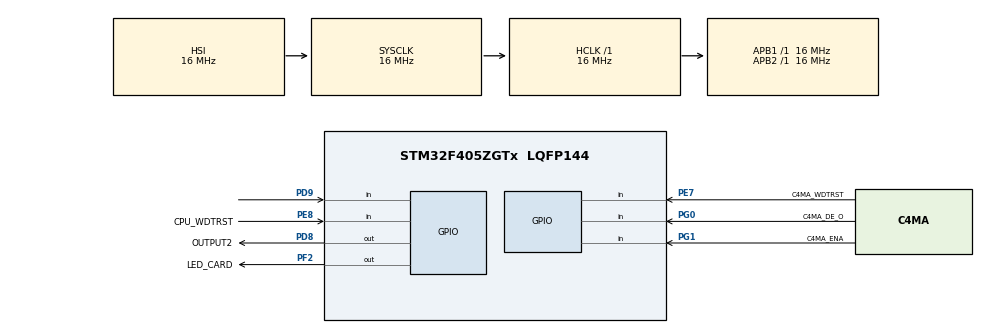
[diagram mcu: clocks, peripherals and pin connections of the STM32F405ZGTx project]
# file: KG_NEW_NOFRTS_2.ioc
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Mcu.Family=STM32F4
Mcu.Name=STM32F405ZGTx
Mcu.Package=LQFP144
NVIC.PriorityGroup=NVIC_PRIORITYGROUP_4
NVIC.TIM3_IRQn=true\:15\:0\:false\:false\:true\:false\:true\:true
NVIC.TimeBase=TIM3_IRQn
NVIC.TimeBaseIP=TIM3
PC12.Signal=UART5_TX
PD2.Signal=UART5_RX
PD8.GPIO_Label=OUTPUT2
PD8.Signal=GPIO_Output
PD9.Signal=GPIO_Input
PE7.GPIO_Label=C4MA_WDTRST
PE7.Signal=GPIO_Input
PE8.GPIO_Label=CPU_WDTRST
PE8.Signal=GPIO_Input
PF2.GPIO_Label=LED_CARD
PF2.Signal=GPIO_Output
PG0.GPIO_Label=C4MA_DE_O
PG0.Signal=GPIO_Input
PG1.GPIO_Label=C4MA_ENA
PG1.Signal=GPIO_Input
PH0-OSC_IN.Mode=HSE-External-Oscillator
PH0-OSC_IN.Signal=RCC_OSC_IN
PH1-OSC_OUT.Mode=HSE-External-Oscillator
PH1-OSC_OUT.Signal=RCC_OSC_OUT
ProjectManager.HeapSize=0x200
ProjectManager.StackSize=0x400
ProjectManager.TargetToolchain=STM32CubeIDE
RCC.48MHZClocksFreq_Value=75000000
RCC.AHBFreq_Value=16000000
RCC.APB1Freq_Value=16000000
RCC.APB2Freq_Value=16000000
RCC.CortexFreq_Value=16000000
RCC.HSE_VALUE=25000000
RCC.HSI_VALUE=16000000
RCC.LSE_VALUE=32768
RCC.PLLSourceVirtual=RCC_PLLSOURCE_HSE
RCC.SYSCLKFreq_VALUE=16000000
RCC.VCOOutputFreq_Value=300000000
VP_SYS_VS_tim3.Mode=TIM3
board=custom

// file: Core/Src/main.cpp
/* USER CODE BEGIN Header */
/**
  ******************************************************************************
  * @file           : main.c
  * @brief          : Main program body
  ******************************************************************************
  * @attention
  *
  * Copyright (c) 2022 STMicroelectronics.
  * All rights reserved.
  *
  * This software is licensed under terms that can be found in the LICENSE file
  * in the root directory of this software component.
  * If no LICENSE file comes with this software, it is provided AS-IS.
  *
  ******************************************************************************
  */
/* USER CODE END Header */
#include "../Inc/main.h"
//#include "usart.h"
#include "gpio.h"

/* USER CODE BEGIN Includes */
//#include "../Mods/RS485_E/M485_E.h"
#include "../Mods/GPIO/MGPIO.h"

/* USER CODE END Includes */

void SystemClock_Config(void);

/* USER CODE BEGIN 0 */
////----------------------------------------------------------------------------
//void HAL_UART_TxCpltCallback( UART_HandleTypeDef *huart ){
//  //__disable_irq();
//  if( huart == g485E.mhUart   )  g485E.onIT_TX();
//
//  //if( huart == gST7580.mhUart )  gST7580.onIT_TX();
// // __enable_irq();
// }//----------------------------------------------------------------------------
//
////----------------------------------------------------------------------------
//void HAL_UART_RxCpltCallback(UART_HandleTypeDef *huart ) {
// // __disable_irq();
//
//  if( huart == g485E.mhUart   )  g485E.onIT_RX();
//	//HAL_GPIO_TogglePin (LED_CARD_GPIO_Port, LED_CARD_Pin);
//	//HAL_UART_Receive_IT(  huart, mRXBuf, 1 );
//
//  //if( huart == gST7580.mhUart )  gST7580.onIT_RX();
//  //__enable_irq();
// }//----------------------------------------------------------------------------

/* USER CODE END 0 */

int main(void)
{

  /* MCU Configuration--------------------------------------------------------*/

  /* Reset of all peripherals, Initializes the Flash interface and the Systick. */
  HAL_Init();

  /* Configure the system clock */
  SystemClock_Config();

  /* Initialize all configured peripherals */
  MX_GPIO_Init();

  //MX_UART5_Init();
  //MX_USART3_UART_Init();
  /* USER CODE BEGIN 2 */
  //_o485E_PwrEN = 0;
  //_o485E_PwrEN_2 = 0;

  //g485E.init( &huart3 );

  /* USER CODE END 2 */

  /* Infinite loop */
  /* USER CODE BEGIN WHILE */
  __enable_irq();

  HAL_GPIO_WritePin(C4MA_DE_O_GPIO_Port,C4MA_DE_O_Pin, GPIO_PIN_SET);
//
//
//
//
//  HAL_GPIO_WritePin(CPU_WDTRST_GPIO_Port,CPU_WDTRST_Pin, GPIO_PIN_SET);
   HAL_GPIO_WritePin(C4MA_WDTRST_GPIO_Port,C4MA_WDTRST_Pin, GPIO_PIN_SET);
//
//  HAL_GPIO_WritePin (LED_CARD_GPIO_Port, LED_CARD_Pin, HAL_GPIO_ReadPin(C4MA_ENA_GPIO_Port, C4MA_ENA_Pin));
//  HAL_GPIO_WritePin (LED_CARD_GPIO_Port, LED_CARD_Pin, GPIO_PIN_SET);
//  HAL_Delay (1000);

  while (1)
  {
    /* USER CODE END WHILE */

    /* USER CODE BEGIN 3 */
//	  for(int i = 0; i < 50000;i++)
//	  {
//
//	  }

	  HAL_GPIO_WritePin (CPU_WDTRST_GPIO_Port, CPU_WDTRST_Pin, GPIO_PIN_RESET);
	  //HAL_Delay(1);
	  for (int i=0; i<100; i++)
	  {

	  }
	  HAL_GPIO_WritePin (CPU_WDTRST_GPIO_Port, CPU_WDTRST_Pin, GPIO_PIN_SET);
	  //HAL_Delay(1);
	  for (int i=0; i<100; i++)
	  	  {

	  	  }
	  HAL_GPIO_WritePin (C4MA_WDTRST_GPIO_Port, C4MA_WDTRST_Pin, GPIO_PIN_RESET);
	  //HAL_Delay(1);
	  for (int i=0; i<100; i++)
	  {

	  }
	  HAL_GPIO_WritePin (C4MA_WDTRST_GPIO_Port, C4MA_WDTRST_Pin, GPIO_PIN_SET);
	  HAL_Delay(5);

//	  HAL_GPIO_TogglePin (CPU_WDTRST_GPIO_Port, CPU_WDTRST_Pin);
//	  HAL_GPIO_TogglePin (C4MA_WDTRST_GPIO_Port, C4MA_WDTRST_Pin);
//	  //HAL_GPIO_TogglePin (OUTPUT2_GPIO_Port, OUTPUT2_Pin);
//
	  HAL_GPIO_WritePin (LED_CARD_GPIO_Port, LED_CARD_Pin, HAL_GPIO_ReadPin(C4MA_ENA_GPIO_Port, C4MA_ENA_Pin));

//	  if (HAL_GPIO_ReadPin(C4MA_ENA_GPIO_Port, C4MA_ENA_Pin) == GPIO_PIN_SET)
//		  HAL_GPIO_WritePin (LED_CARD_GPIO_Port, LED_CARD_Pin, GPIO_PIN_RESET);
//	  else
//		  HAL_GPIO_WritePin (LED_CARD_GPIO_Port, LED_CARD_Pin, GPIO_PIN_SET);

	  HAL_Delay (200);   /* Insert delay 100 ms */

	  //g485E.sendTX_TEST();

	  //HAL_Delay (100);
  }
  /* USER CODE END 3 */
}

void SystemClock_Config(void)
{
  RCC_OscInitTypeDef RCC_OscInitStruct = {0};
  RCC_ClkInitTypeDef RCC_ClkInitStruct = {0};

  /** Configure the main internal regulator output voltage
  */
  __HAL_RCC_PWR_CLK_ENABLE();
  __HAL_PWR_VOLTAGESCALING_CONFIG(PWR_REGULATOR_VOLTAGE_SCALE1);

  /** Initializes the RCC Oscillators according to the specified parameters
  * in the RCC_OscInitTypeDef structure.
  */
  RCC_OscInitStruct.OscillatorType = RCC_OSCILLATORTYPE_HSI;
  RCC_OscInitStruct.HSIState = RCC_HSI_ON;
  RCC_OscInitStruct.HSICalibrationValue = RCC_HSICALIBRATION_DEFAULT;
  RCC_OscInitStruct.PLL.PLLState = RCC_PLL_NONE;
  if (HAL_RCC_OscConfig(&RCC_OscInitStruct) != HAL_OK)
  {
    Error_Handler();
  }

  /** Initializes the CPU, AHB and APB buses clocks
  */
  RCC_ClkInitStruct.ClockType = RCC_CLOCKTYPE_HCLK|RCC_CLOCKTYPE_SYSCLK
                              |RCC_CLOCKTYPE_PCLK1|RCC_CLOCKTYPE_PCLK2;
  RCC_ClkInitStruct.SYSCLKSource = RCC_SYSCLKSOURCE_HSI;
  RCC_ClkInitStruct.AHBCLKDivider = RCC_SYSCLK_DIV1;
  RCC_ClkInitStruct.APB1CLKDivider = RCC_HCLK_DIV1;
  RCC_ClkInitStruct.APB2CLKDivider = RCC_HCLK_DIV1;

  if (HAL_RCC_ClockConfig(&RCC_ClkInitStruct, FLASH_LATENCY_0) != HAL_OK)
  {
    Error_Handler();
  }
}

/* USER CODE BEGIN 4 */
//#include "../Mods/RS485_E/M485_E_cpp.h"
//#include "../Mods/RS485_E/M485_E_cpp_TX.h"
/* USER CODE END 4 */

void HAL_TIM_PeriodElapsedCallback(TIM_HandleTypeDef *htim)
{
  if (htim->Instance == TIM3) {
    HAL_IncTick();
  }
}

void Error_Handler(void)
{
  __disable_irq();
  while (1)
  {
  }
}
